# RS14100 register map
File version: 1.0
CPU: CM4 r0p1, little endian, MPU, FPU, 4 interrupt priority bits
Registers are 32-bit, read-write, reset 0x0 unless marked. A register's access mark holds for its fields unless they carry their own. Offsets are from the block's base; [hi:lo] are bit positions.

## ProcessSensor — The process sensor module, count the process clock (high frequency ring clock) over one MCU FSM clock and divide this clock by programmable value.
Base 0x24048540
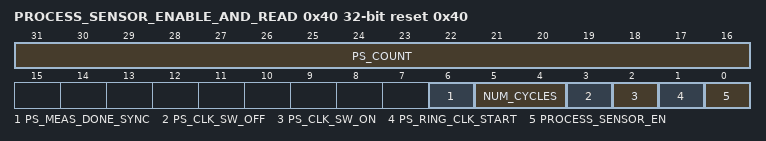
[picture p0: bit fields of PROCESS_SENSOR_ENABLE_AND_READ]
0x40 PROCESS_SENSOR_ENABLE_AND_READ reset 0x40 — Process sensor enable and read for operation
  [31:16] PS_COUNT ro — Processor sensor read back
  [6] PS_MEAS_DONE_SYNC ro — Processor sensor measurement done.
  [5:4] NUM_CYCLES — Number of MCU FSM clock(32KHz)for which measurement need to be done.if bits is 1 then 1 clock, 2 then 2 clocks,3 then 3 clocks,4 then 4 clocks.
  [3] PS_CLK_SW_OFF — Clock cleaner off signal to clock cleaner block on clock generated by delay chain.
  [2] PS_CLK_SW_ON — Clock cleaner on signal to clock cleaner block on clock generated by delay chain.
  [1] PS_RING_CLK_START — Start Ring-Oscillator clock for estimating process corner.
  [0] PROCESS_SENSOR_EN — enable or on the process sensor,if this bit is set the sensor enable else sensor is disable.

## TEMPERATURE_SENSOR — The temperature sensor is used to read the temperature by using APB registers, which is access through direct to ULPSS system.
Base 0x24048500
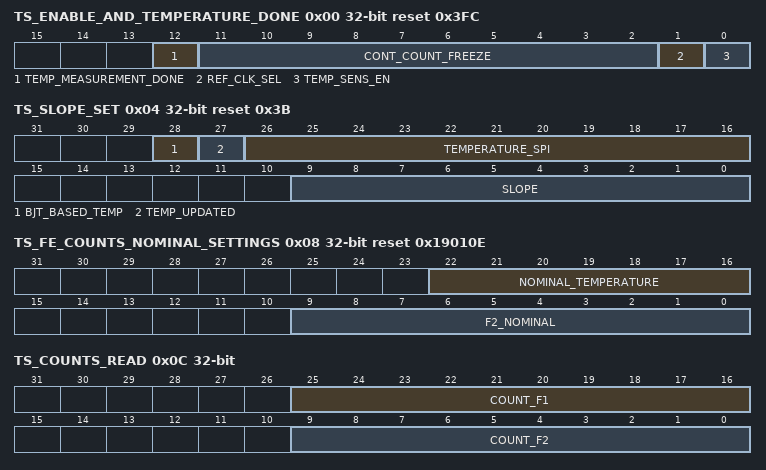
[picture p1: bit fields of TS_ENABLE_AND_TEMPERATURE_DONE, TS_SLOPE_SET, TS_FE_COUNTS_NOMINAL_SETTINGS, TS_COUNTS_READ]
0x00 TS_ENABLE_AND_TEMPERATURE_DONE reset 0x3FC — Temperature sensor enable and measurement calculation done indication register
  [12] TEMP_MEASUREMENT_DONE ro — temperature measurement done indication.
  [11:2] CONT_COUNT_FREEZE — Count of reference clock on which ptat clock counts
  [1] REF_CLK_SEL — if this bit is zero then reference RO clock from analog,else this bit is one then MCU FSM clock
  [0] TEMP_SENS_EN wo — Temperature sensing enable,self clearing register
0x04 TS_SLOPE_SET reset 0x3B — temperature sensor slope set(slope will be change with respect to temperature change)
  [28] BJT_BASED_TEMP — Temperature is updated through which is calculated using bjt based if bit is high(1) through spi and bit is low(0) then through calculation RO based
  [27] TEMP_UPDATED wo — temperature updated signal for the reg to capture this temperature.
  [26:16] TEMPERATURE_SPI — temperature known
  [9:0] SLOPE — This is one time measurement for one package after chip arrives from fab,this is signed bit.
0x08 TS_FE_COUNTS_NOMINAL_SETTINGS reset 0x19010E — determine calibrated temperature
  [22:16] NOMINAL_TEMPERATURE — calibrated temperature
  [9:0] F2_NOMINAL — ptat clock count during calibration,This will vary with chip to chip.
0x0C TS_COUNTS_READ ro — temperature sensor count read.
  [25:16] COUNT_F1, [9:0] COUNT_F2
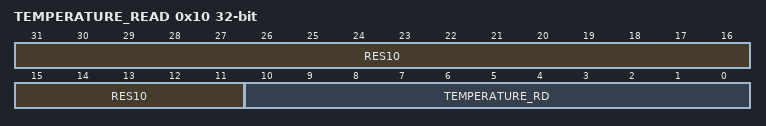
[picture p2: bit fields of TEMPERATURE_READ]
0x10 TEMPERATURE_READ — read the temperature
  [31:11] RES10 — reserved10
  [10:0] TEMPERATURE_RD ro — Temperature value for read in signed format

## FIM — FIM support fixed point Multiplications implemented through programmable shifting.
Base 0x24070000
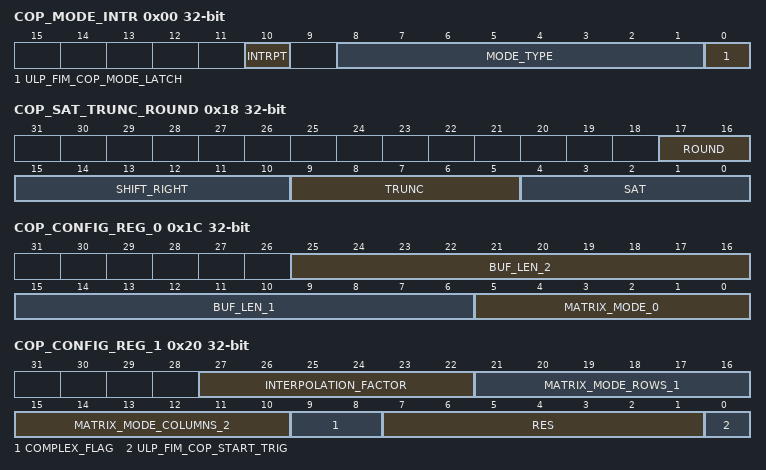
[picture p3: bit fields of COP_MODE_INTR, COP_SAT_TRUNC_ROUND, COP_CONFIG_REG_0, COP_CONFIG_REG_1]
0x00 COP_MODE_INTR reset not defined — This register used for COP mode interrupt register.
  [10] INTRPT — Writing 1 to this bit clears the interrupt
  [8:1] MODE_TYPE — to define mode for those bit are used mode like FIR,IIR,INTERPOLATE etc
  [0] ULP_FIM_COP_MODE_LATCH — mode switch: Writing 1 into this latches the mode internally
0x04 COP_INPUT_ADDR_0 reset not defined — This register used for COP input address for 0 register.
  [12:0] ULP_OFFSET_ADDR_0 — 13 bit word aligned ULP address offset of data set 0.used by all modes
0x08 COP_INPUT_ADDR_1 reset not defined — This register used for COP input address for 1 register.
  [12:0] ULP_OFFSET_ADDR_1 — 13 bit Word Aligned ULP Address Offset of Data set 1.used by all modes except, scalar and norm_square.
0x0C COP_OUTPUT_ADDR reset not defined — This register used for COP output address register.
  [12:0] ULP_ADDR_OUT_DATA — 13 bit Word Aligned ULP Address Offset of Output Data.
0x10 COP_DATA0 reset not defined — This register used for COP data for 0 register.
  [31:0] POLE_0_SCALAR — Pole 0/Scalar Value
0x14 COP_DATA1 reset not defined — This register used for COP data for 1 register.
  [31:0] POLE_1
0x18 COP_SAT_TRUNC_ROUND reset not defined — This register used for COP saturated and truncate register.
  [17:16] ROUND
  [15:10] SHIFT_RIGHT — Right shift value
  [9:5] TRUNC — truncate
  [4:0] SAT — Saturate
0x1C COP_CONFIG_REG_0 reset not defined — This register used for COP configuration register 0.
  [25:16] BUF_LEN_2 — buffer length 2,buffer length of data set 1
  [15:6] BUF_LEN_1 — buffer length 1,buffer length of data set 1
  [5:0] MATRIX_MODE_0 — Matrix mode Num_Of Colums in Matrix 1/Num_Of Rows in Matrix 2.
0x20 COP_CONFIG_REG_1 reset not defined — This register used for COP configuration register 1.
  [27:22] INTERPOLATION_FACTOR
  [21:16] MATRIX_MODE_ROWS_1 — Matrix mode,Number Of rows in matrix 1
  [15:10] MATRIX_MODE_COLUMNS_2 — Matrix mode,Num_Of columns in matrix 2
  [9:8] COMPLEX_FLAG — Complex Flag,not valid in matrix mode
  [7:1] RES ro — reserved5
  [0] ULP_FIM_COP_START_TRIG wo — Start trigger for the FIMQ operations,this is reset upon write register
